AUTOSAR XML (schema 314)
package /ComponentType
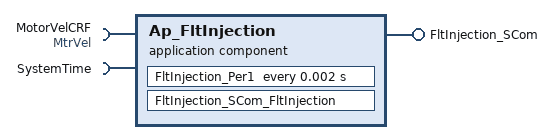
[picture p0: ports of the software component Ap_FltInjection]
  application software component type Ap_FltInjection
    provide port FltInjection_SCom: server-com-spec{operation=FltInjection, queue-length=1}, provided-interface=FltInjection_SCom
    require port MotorVelCRF: unqueued-receiver-com-spec{data-element=MtrRadpS_f32, init-value=D_ZERO_ULS_F32}, required-interface=MtrVel
    require port SystemTime: required-interface=SystemTime
      required-com-specs:
        DtrmnElapsedTime_mS_u16
        DtrmnElapsedTime_mS_u32
        DtrmnElapsedTime_uS_u16
        DtrmnElapsedTime_uS_u32
        GetSystemTime_mS_u32
        GetSystemTime_uS_u32
  internal behavior Ap_FltInjection_InternalBehavior: component=Ap_FltInjection
    timing event TMT_FltInjection_Per1: start-on-event=FltInjection_Per1, period=0.002
    operation invoked event OIT_FltInjection_SCom_FltInjection_FltInjection_SCom_FltInjection: start-on-event=FltInjection_SCom_FltInjection, operation=FltInjection_SCom.FltInjection
    port-api-options:
      enable-take-address=false, indirect-api=false, port=FltInjection_SCom
      enable-take-address=false, indirect-api=false, port=MotorVelCRF
      enable-take-address=false, indirect-api=false, port=SystemTime
    runnable FltInjection_Per1
      data read access READ_MotorVelCRF_MtrRadpS_f32: data-element=MotorVelCRF.MtrRadpS_f32
      sync call SC_SystemTime_DtrmnElapsedTime_mS_u32: operation=SystemTime.DtrmnElapsedTime_mS_u32, timeout=0
      sync call SC_SystemTime_GetSystemTime_mS_u32: operation=SystemTime.GetSystemTime_mS_u32, timeout=0
    runnable FltInjection_SCom_FltInjection: can-be-invoked-concurrently=true
  swc implementation Ap_FltInjection_Implementation: behavior=Ap_FltInjection_InternalBehavior
    code-descriptors:
      code Code: type=SRC
